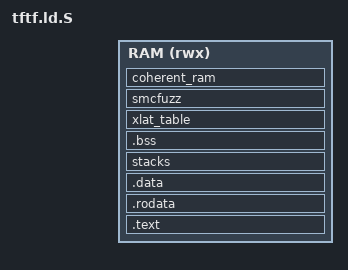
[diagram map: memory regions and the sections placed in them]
/*
 * Copyright (c) 2020-2022, Arm Limited. All rights reserved.
 *
 * SPDX-License-Identifier: BSD-3-Clause
 */

#include <platform_def.h>
#include <xlat_tables_defs.h>

OUTPUT_FORMAT(PLATFORM_LINKER_FORMAT)
OUTPUT_ARCH(PLATFORM_LINKER_ARCH)
ENTRY(tftf_entrypoint)

#ifndef TFTF_MAX_IMAGE_SIZE
#define TFTF_MAX_IMAGE_SIZE DRAM_SIZE
#endif

MEMORY {
    RAM (rwx): ORIGIN = TFTF_BASE, LENGTH = TFTF_MAX_IMAGE_SIZE
}


SECTIONS
{
    . = TFTF_BASE;
    __TFTF_BASE__ = .;

    .text . : {
        __TEXT_START__ = .;
        *entrypoint.o(.text*)
        *(.text*)
        *(.vectors)
        . = NEXT(PAGE_SIZE);
        __TEXT_END__ = .;
    } >RAM

    .rodata . : {
        __RODATA_START__ = .;
        *(.rodata*)
        /*
         * Memory page(s) mapped to this section will be marked as
         * read-only, executable.  No RW data from the next section must
         * creep in.  Ensure the rest of the current memory page is unused.
         */
        . = NEXT(PAGE_SIZE);
        __RODATA_END__ = .;
    } >RAM

    .data : {
        __DATA_START__ = .;
        *(.data*)
        __DATA_END__ = .;
    } >RAM

    stacks (NOLOAD) : {
        __STACKS_START__ = .;
        *(tftf_normal_stacks)
        __STACKS_END__ = .;
    } >RAM

    /*
     * The .bss section gets initialised to 0 at runtime.
     * Its base address must be 16-byte aligned.
     */
    .bss : ALIGN(16) {
        __BSS_START__ = .;
        *(SORT_BY_ALIGNMENT(.bss*))
        *(COMMON)
        __BSS_END__ = .;
    } >RAM

    /*
     * The xlat_table section is for full, aligned page tables (4K).
     * Removing them from .bss avoids forcing 4K alignment on
     * the .bss section and eliminates the unecessary zero init
     */
    xlat_table (NOLOAD) : {
        *(xlat_table)
    } >RAM

    /*
     * The SMC fuzzing module requires alignment due to malloc
     * constraints. Also size must be at least around 64K
     */
    smcfuzz (NOLOAD) : {
        *(smcfuzz)
    } >RAM

    /*
     * The base address of the coherent memory section must be page-aligned (4K)
     * to guarantee that the coherent data are stored on their own pages and
     * are not mixed with normal data.  This is required to set up the correct
     * memory attributes for the coherent data page tables.
     */
    coherent_ram (NOLOAD) : ALIGN(PAGE_SIZE) {
        __COHERENT_RAM_START__ = .;
        *(tftf_coherent_stacks)
        *(tftf_coherent_mem)
        __COHERENT_RAM_END_UNALIGNED__ = .;
        /*
         * Memory page(s) mapped to this section will be marked
         * as device memory.  No other unexpected data must creep in.
         * Ensure the rest of the current memory page is unused.
         */
        . = NEXT(PAGE_SIZE);
        __COHERENT_RAM_END__ = .;
    } >RAM

    __COHERENT_RAM_UNALIGNED_SIZE__ =
        __COHERENT_RAM_END_UNALIGNED__ - __COHERENT_RAM_START__;


    __TFTF_END__ = .;

    __BSS_SIZE__ = SIZEOF(.bss);

}
